# STM32L4R5AGI6 register map
File version: 1.0
Registers are 32-bit, access not given, reset 0x0 unless marked. A register's access mark holds for its fields unless they carry their own. Offsets are from the block's base; [hi:lo] are bit positions; {n}, {i} and the like mark numbered series; 'fields as' and 'values as' point back to an identical list.

## AES
Base 0x50060000
0x00 CR
  [23:20] NPBLB, [18] KEYSIZE, [31:15] s, [14:13] GCMPH, [12] DMAOUTEN, [11] DMAINEN, [10] ERRIE, [9] CCFIE, [8] ERRC, [7] CCFC, [16:5] CHMOD, [4:3] MODE, [2:1] DATATYPE, [0] EN
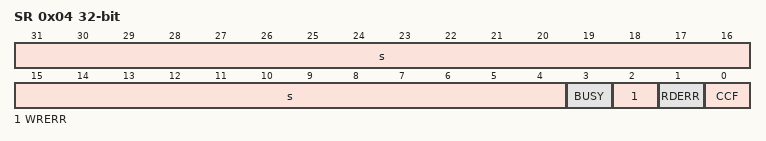
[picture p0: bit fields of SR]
0x04 SR
  [31:4] s, [3] BUSY, [2] WRERR, [1] RDERR, [0] CCF
0x08 DINR
  [31:0] DIN
0x0C DOUTR
  [31:0] DOUT
{0x10+4i} KEYR{i} (i=0..3)
  [31:0] KEY
{0x20+4i} IVR{i} (i=0..3)
  [31:0] IVI
{0x20+4i} KEYR{i} (i=4..7)
  [31:0] KEY
{0x40+4i} SUSP{i}R (i=0..7)
  [31:0] SUSP

## HASH
Base 0x50060400
0x00 CR
  [16] LKEY, [13] MDMAT, [12] DINNE, [11:8] NBW, [18:7] ALGO, [6] MODE, [5:4] DATATYPE, [3] DMAE, [2] INIT, [31:0] s
0x04 DIN
  [31:0] DATAIN
0x08 STR
  [8] DCAL, [31:5] s, [4:0] NBLW
{0xC+4i} HRA{i} (i=0..4)
  [31:0] H{i}
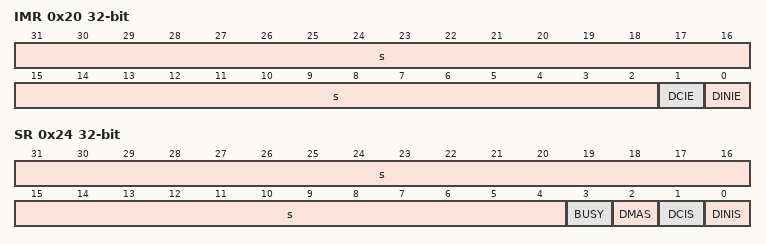
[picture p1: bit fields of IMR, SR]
0x20 IMR
  [31:2] s, [1] DCIE, [0] DINIE
0x24 SR
  [31:4] s, [3] BUSY, [2] DMAS, [1] DCIS, [0] DINIS
{0xF8+4i} CSR{i} (i=0..53)
  [31:0] CSx
{0x310+4i} HR{i} (i=0..7)
  [31:0] H{i}

## RNG
Base 0x50060800
0x00 CR
  [31] CONFIGLOCK, [30] CONDRST, [25:20] RNG_CONFIG1, [19:16] CLKDIV, [15:13] RNG_CONFIG2, [12] NISTC, [11:8] RNG_CONFIG3, [5] CED, [3] IE, [2] RNGEN, [29:0] s
0x04 SR
  [6] SEIS, [5] CEIS, [31:3] s, [2] SECS, [1] CECS, [0] DRDY
0x08 DR
  [31:0] RNDATA
0x10 HTCR
  [31:0] HTCFG

## OCTOSPIM
Base 0x50061C00
0x00 CR
  [23:16] REQ2ACK_TIME, [31:1] s, [0] MUXEN
0x04 P1CR
  [26:25] IOHSRC, [24] IOHEN, [18:17] IOLSRC, [16] IOLEN, [9] NCSSRC, [8] NCSEN, [5] DQSSRC, [4] DQSEN, [31:2] s, [1] CLKSRC, [0] CLKEN
0x08 P2CR
  fields as P1CR

## SDMMC1
Base 0x50062400
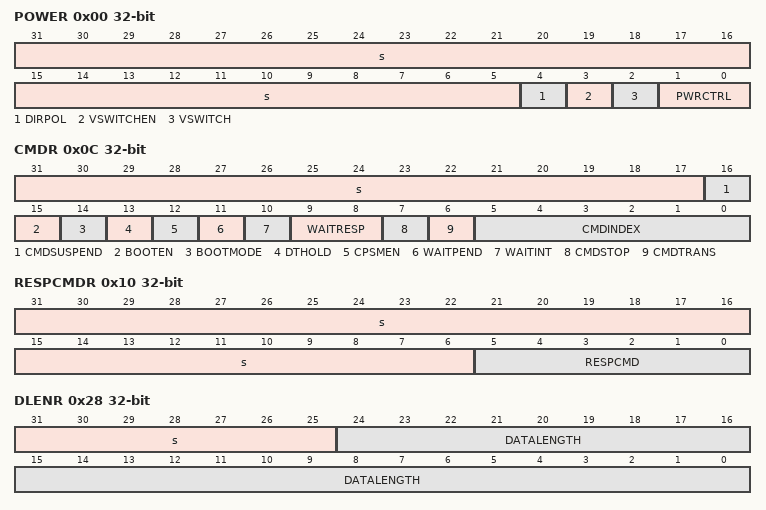
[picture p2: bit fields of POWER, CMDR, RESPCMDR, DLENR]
0x00 POWER
  [31:5] s, [4] DIRPOL, [3] VSWITCHEN, [2] VSWITCH, [1:0] PWRCTRL
0x04 CLKCR
  [21:20] SELCLKRX, [19] BUSSPEED, [18] DDR, [17] HWFC_EN, [16] NEGEDGE, [15:14] WIDBUS, [12] PWRSAV, [31:10] s, [9:0] CLKDIV
0x08 ARGR
  [31:0] CMDARG
0x0C CMDR
  [31:17] s, [16] CMDSUSPEND, [15] BOOTEN, [14] BOOTMODE, [13] DTHOLD, [12] CPSMEN, [11] WAITPEND, [10] WAITINT, [9:8] WAITRESP, [7] CMDSTOP, [6] CMDTRANS, [5:0] CMDINDEX
0x10 RESPCMDR
  [31:6] s, [5:0] RESPCMD
{0x10+4i} RESP{i}R (i=1..4)
  [31:0] CARDSTATUS{i}
0x24 DTIMER
  [31:0] DATATIME
0x28 DLENR
  [31:25] s, [24:0] DATALENGTH
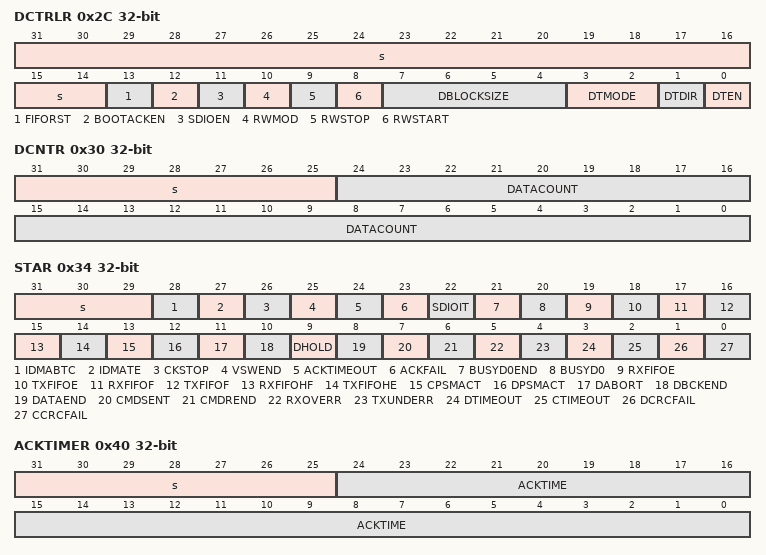
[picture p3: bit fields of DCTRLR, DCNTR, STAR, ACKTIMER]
0x2C DCTRLR
  [31:14] s, [13] FIFORST, [12] BOOTACKEN, [11] SDIOEN, [10] RWMOD, [9] RWSTOP, [8] RWSTART, [7:4] DBLOCKSIZE, [3:2] DTMODE, [1] DTDIR, [0] DTEN
0x30 DCNTR
  [31:25] s, [24:0] DATACOUNT
0x34 STAR
  [31:29] s, [28] IDMABTC, [27] IDMATE, [26] CKSTOP, [25] VSWEND, [24] ACKTIMEOUT, [23] ACKFAIL, [22] SDIOIT, [21] BUSYD0END, [20] BUSYD0, [19] RXFIFOE, [18] TXFIFOE, [17] RXFIFOF, [16] TXFIFOF, [15] RXFIFOHF, [14] TXFIFOHE, [13] CPSMACT, [12] DPSMACT, [11] DABORT, [10] DBCKEND, [9] DHOLD, [8] DATAEND, [7] CMDSENT, [6] CMDREND, [5] RXOVERR, [4] TXUNDERR, [3] DTIMEOUT, [2] CTIMEOUT, [1] DCRCFAIL, [0] CCRCFAIL
0x38 ICR
  [28] IDMABTCC, [27] IDMATEC, [26] CKSTOPC, [25] VSWENDC, [24] ACKTIMEOUTC, [23] ACKFAILC, [22] SDIOITC, [21] BUSYD0ENDC, [31:12] s, [11] DABORTC, [10] DBCKENDC, [9] DHOLDC, [8] DATAENDC, [7] CMDSENTC, [6] CMDRENDC, [5] RXOVERRC, [4] TXUNDERRC, [3] DTIMEOUTC, [2] CTIMEOUTC, [1] DCRCFAILC, [0] CCRCFAILC
0x3C MASKR
  [28] IDMABTCIE, [26] CKSTOPIE, [25] VSWENDIE, [24] ACKTIMEOUTIE, [23] ACKFAILIE, [22] SDIOITIE, [21] BUSYD0ENDIE, [18] TXFIFOEIE, [17] RXFIFOFIE, [15] RXFIFOHFIE, [14] TXFIFOHEIE, [31:12] s, [11] DABORTIE, [10] DBCKENDIE, [9] DHOLDIE, [8] DATAENDIE, [7] CMDSENTIE, [6] CMDRENDIE, [5] RXOVERRIE, [4] TXUNDERRIE, [3] DTIMEOUTIE, [2] CTIMEOUTIE, [1] DCRCFAILIE, [0] CCRCFAILIE
0x40 ACKTIMER
  [31:25] s, [24:0] ACKTIME
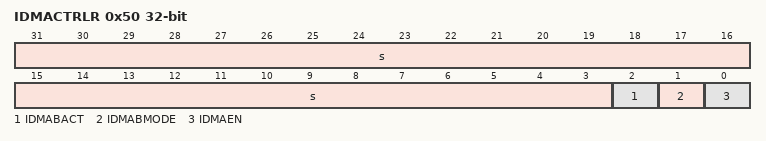
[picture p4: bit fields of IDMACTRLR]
0x50 IDMACTRLR
  [31:3] s, [2] IDMABACT, [1] IDMABMODE, [0] IDMAEN
0x54 IDMABSIZER
  [12:5] IDMABNDT, [31:0] s
0x58 IDMABASE0R
  [31:0] IDMABASE0
0x5C IDMABASE1R
  [31:0] IDMABASE1
0x80 FIFOR.0
  [31:0] FIFODATA
0x84 FIFOR.1
  [31:0] FIFODATA
0x88 FIFOR.2
  [31:0] FIFODATA
0x8C FIFOR.3
  [31:0] FIFODATA
0x90 FIFOR.4
  [31:0] FIFODATA
0x94 FIFOR.5
  [31:0] FIFODATA
0x98 FIFOR.6
  [31:0] FIFODATA
0x9C FIFOR.7
  [31:0] FIFODATA
0xA0 FIFOR.8
  [31:0] FIFODATA
0xA4 FIFOR.9
  [31:0] FIFODATA
0xA8 FIFOR.10
  [31:0] FIFODATA
0xAC FIFOR.11
  [31:0] FIFODATA
0xB0 FIFOR.12
  [31:0] FIFODATA
0xB4 FIFOR.13
  [31:0] FIFODATA
0xB8 FIFOR.14
  [31:0] FIFODATA
0xBC FIFOR.15
  [31:0] FIFODATA

## FSMC
Base 0xA0000000
0x00 BCR1
  [23:22] NBLSET, [21] WFDIS, [20] CCLKEN, [19] CBURSTRW, [18:16] CPSIZE, [15] ASYNCWAIT, [14] EXTMOD, [13] WAITEN, [12] WREN, [11] WAITCFG, [9] WAITPOL, [8] BURSTEN, [31:7] s, [6] FACCEN, [5:4] MWID, [3:2] MTYP, [1] MUXEN, [0] MBKEN
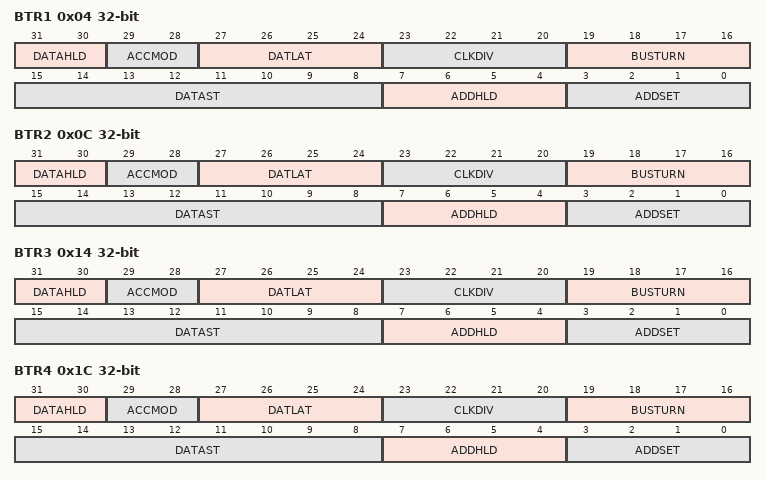
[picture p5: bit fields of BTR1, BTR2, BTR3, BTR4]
0x04 BTR1
  [31:30] DATAHLD, [29:28] ACCMOD, [27:24] DATLAT, [23:20] CLKDIV, [19:16] BUSTURN, [15:8] DATAST, [7:4] ADDHLD, [3:0] ADDSET
0x08 BCR2
  [23:22] NBLSET, [19] CBURSTRW, [18:16] CPSIZE, [15] ASYNCWAIT, [14] EXTMOD, [13] WAITEN, [12] WREN, [11] WAITCFG, [9] WAITPOL, [8] BURSTEN, [31:7] s, [6] FACCEN, [5:4] MWID, [3:2] MTYP, [1] MUXEN, [0] MBKEN
0x0C BTR2
  fields as BTR1
0x10 BCR3
  fields as BCR2
0x14 BTR3
  fields as BTR1
0x18 BCR4
  fields as BCR2
0x1C BTR4
  fields as BTR1
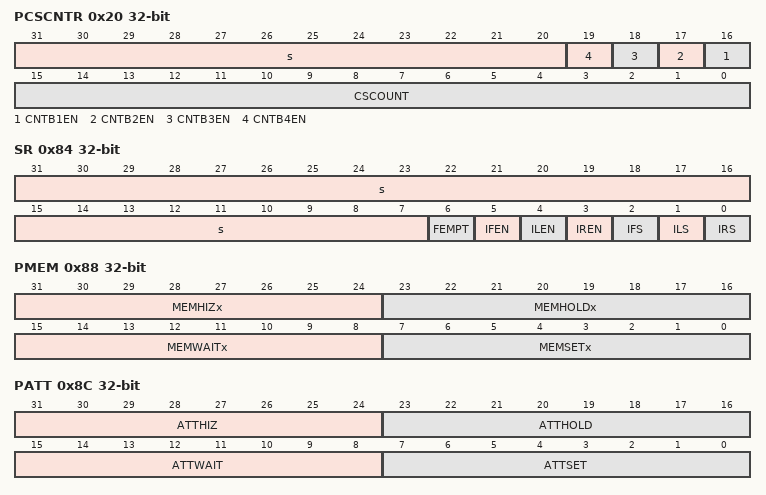
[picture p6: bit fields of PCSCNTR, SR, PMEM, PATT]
0x20 PCSCNTR
  [31:20] s, [n+15] CNTB{n}EN (n=1..4), [15:0] CSCOUNT
0x80 PCR
  [19:17] ECCPS, [16:13] TAR, [12:9] TCLR, [6] ECCEN, [5:4] PWID, [3] PTYP, [2] PBKEN, [1] PWAITEN, [31:0] s
0x84 SR
  [31:7] s, [6] FEMPT, [5] IFEN, [4] ILEN, [3] IREN, [2] IFS, [1] ILS, [0] IRS
0x88 PMEM
  [31:24] MEMHIZx, [23:16] MEMHOLDx, [15:8] MEMWAITx, [7:0] MEMSETx
0x8C PATT
  [31:24] ATTHIZ, [23:16] ATTHOLD, [15:8] ATTWAIT, [7:0] ATTSET
0x94 ECCR
  [31:0] ECCx
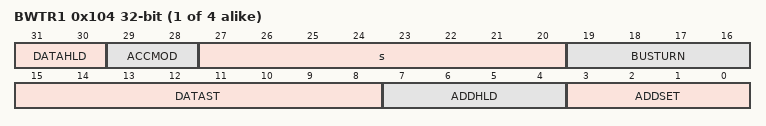
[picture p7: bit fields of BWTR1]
{0xFC+8i} BWTR{i} (i=1..4)
  [31:30] DATAHLD, [29:28] ACCMOD, [27:20] s, [19:16] BUSTURN, [15:8] DATAST, [7:4] ADDHLD, [3:0] ADDSET

## OCTOSPI1
Base 0xA0001000
Same registers: OCTOSPI2 0xA0001400
0x00 CR
  [29:28] FMDOE, [23] PMM, [22] APMS, [20] TOIE, [19] SMIE, [18] FTIE, [17] TCIE, [16] TEIE, [12:8] FTHRES, [7] FSEL, [6] DMM, [31:4] s, [3] TCEN, [2] DMAEN, [1] ABORT, [0] EN
0x08 DCR1
  [26:24] MTYP, [20:16] DEVSIZE, [13:8] CSHT, [3] DLYBYP, [31:2] s, [1] FRCK, [0] CKMODE
0x0C DCR2
  [18:16] WRAPSIZE, [31:8] s, [7:0] PRESCALER
0x10 DCR3
  [20:16] CSBOUND, [31:8] s, [7:0] MAXTRAN
0x14 DCR4
  [31:0] REFRESH
0x20 SR
  [13:8] FLEVEL, [31:6] s, [5] BUSY, [4] TOF, [3] SMF, [2] FTF, [1] TCF, [0] TEF
0x24 FCR
  [4] CTOF, [3] CSMF, [31:2] s, [1] CTCF, [0] CTEF
0x40 DLR
  [31:0] DL
0x48 AR
  [31:0] ADDRESS
0x50 DR
  [31:0] DATA
0x80 PSMKR
  [31:0] MASK
0x88 PSMAR
  [31:0] MATCH
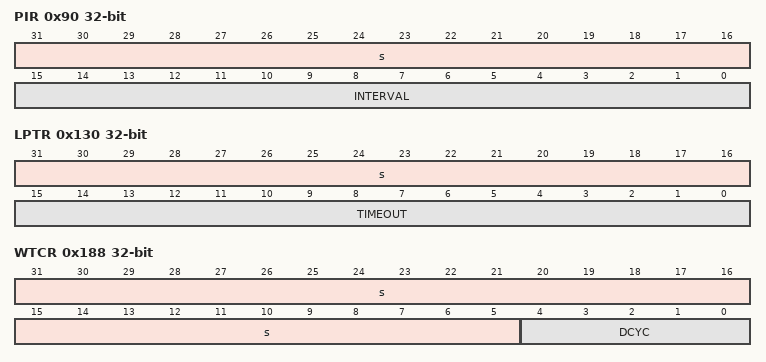
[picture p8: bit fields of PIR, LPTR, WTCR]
0x90 PIR
  [31:16] s, [15:0] INTERVAL
0x100 CCR
  [31] SIOO, [29] DQSE, [27] DDTR, [26:24] DMODE, [21:20] ABSIZE, [19] ABDTR, [18:16] ABMODE, [13:12] ADSIZE, [11] ADDTR, [10:8] ADMODE, [30:6] s, [5:4] ISIZE, [3] IDTR, [2:0] IMODE
0x108 TCR
  [30] SSHIFT, [28] DHQC, [31:5] s, [4:0] DCYC
0x110 IR
  [31:0] INSTRUCTION
0x120 ABR
  [31:0] ALTERNATE
0x130 LPTR
  [31:16] s, [15:0] TIMEOUT
0x140 WPCCR
  [29] DQSE, [27] DDTR, [26:24] DMODE, [21:20] ABSIZE, [19] ABDTR, [18:16] ABMODE, [13:12] ADSIZE, [11] ADDTR, [10:8] ADMODE, [31:6] s, [5:4] ISIZE, [3] IDTR, [2:0] IMODE
0x148 WPTCR
  [30] SSHIFT, [28] DHQC, [31:5] s, [4:0] DCYC
0x150 WPIR
  [31:0] INSTRUCTION
0x160 WPABR
  [31:0] ALTERNATE
0x180 WCCR
  fields as WPCCR
0x188 WTCR
  [31:5] s, [4:0] DCYC
0x190 WIR
  [31:0] INSTRUCTION
0x1A0 WABR
  [31:0] ALTERNATE
0x200 HLCR
  [23:16] TRWR, [15:8] TACC, [31:2] s, [1] WZL, [0] LM
